# 3061MNNIKA register map
File version: 1.0
Registers are 32-bit, access per field, reset 0x0 unless marked. A register's access mark holds for its fields unless they carry their own. Offsets are from the block's base; [hi:lo] are bit positions.

## I2C0 — I2C peripheral interface
Base 0x14100000
Same registers: I2C1 0x14101000
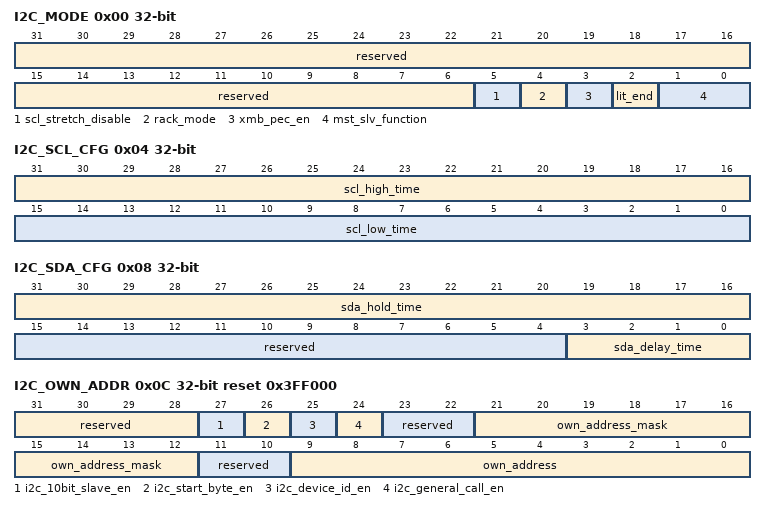
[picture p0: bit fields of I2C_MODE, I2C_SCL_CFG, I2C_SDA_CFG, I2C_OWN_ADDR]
0x00 I2C_MODE — I2C模式配置寄存器。
  [31:6] reserved ro — 保留。
  [5] scl_stretch_disable rw — SCL Stretching使能位。 使能后若如下条件满足，拉低SCL并保持到条件不满足。 不使能时，即使条件满足，SCL也不会被拉低。 该使能位同时对Master和Slave生效。 0：使能； 1：不使能。
  [4] rack_mode rw — 接收ACK/NACK的模式。 0：严格ACK/NACK。如果Master-Transmitter接收到的ACK/NACK与配置的时序命令所期望的ACK/NACK不匹配，那么发出STOP condition，自动退出Master。如果Slave-Transmitter接收到的ACK/NACK与配置的时序命令所期望的ACK/NACK不匹配，那么Slave退出当前I2C帧的通信，SDA输出高阻。 1：忽略ACK/NACK。如果Master-Transmitter，或Slave-Transmitter接收到的ACK/NACK与配置的时序命令所期望的ACK/NACK不匹配，忽略此不匹配，继续下一个时序命令。
  [3] xmb_pec_en rw — SMBus和PMBus的PEC（CRC-8，多项式0x07）计算使能。使能此位后，I2C控制器会自动计算PEC。软件需要通过时序命令控制是否发送PEC和接收PEC。 0：SMBus PEC不使能计算； 1：SMBus PEC使能计算。
  [2] lit_end rw — 数据传输顺序。对Master和Slave功能有效。 0 ：MSbit-First模式； 1 ：LSbit-First模式。
  [1:0] mst_slv_function rw — Master功能和Slave功能选择。 00：控制器不使能； 01：控制器处于Master-only模式； 10：控制器处于Slave-only模式； 11：控制器处于Master-Slave模式。
0x04 I2C_SCL_CFG rw — I2C SCL高低电平时间寄存器。
  [31:16] scl_high_time — SCL高电平时长。Master有效。 建议在标准模式下为SCL周期的1/2，快速模式下为SCL周期的0.36。 标准模式下 (fSCL为SCL时钟线的频率)： scl_high_time = (fclk_i2c/fSCL) x 0.5 - 8 - spike_filter_time 快速模式下 (FSCL为SCL时钟线的频率)： scl_high_time = (fclk_i2c/fSCL) x 0.36 - 8 - spike_filter_time 以参考时钟为100MHz且工作在快速模式下(fSCL = 400kHz)为例，若不滤波，scl_high_time =(100MHz / 400kHz) x 0.36 - 8 = 82。
  [15:0] scl_low_time — SCL低电平时长。Master有效。 建议在标准模式下为SCL周期的1/2，快速模式下为SCL周期的0.64。 标准模式下 (fSCL为SCL时钟线的频率)： scl_low_time = (fclk_i2c/fSCL) x 0.5 - 9 - spike_filter_time 快速模式下 (fSCL为SCL时钟线的频率)： scl_low_time = (fclk_i2c/fSCL) x 0.64 - 9 - spike_filter_time 以参考时钟为100Mhz且工作在快速模式下(fSCL = 400 kHz)为例，若不滤波，，scl_low_time =(100MHz / 400kHz) x 0.64 - 9 = 151。
0x08 I2C_SDA_CFG — I2C SDA时序配置寄存器。
  [31:16] sda_hold_time rw — SDA保持时间配置。 建议配置为sda_hold_duration = i2c_low_duration * 0.3。 注意：只能控制SDA输出的hold time时长。
  [15:4] reserved ro — 保留。
  [3:0] sda_delay_time rw — SDA延迟采样配置。延迟sda_delay_time个clk_i2c工作时钟周期。 注意：对SDA进行delay是指从SDA管脚进来的信号经过寄存后再送给内部控制器。此域决定SDA延迟多少个工作时钟周期后才进行采样。
0x0C I2C_OWN_ADDR reset 0x3FF000 — I2C Slave地址配置寄存器。
  [31:28] reserved ro — 保留。
  [27] i2c_10bit_slave_en rw — I2C控制器Slave接收10bit Slave Addressing (0b1111 0xx)，也正常接收7bit地址。 0：不使能，即7bit寻址模式；Slave将10bit Slave Addressing (0b1111 0xx)视为普通地址，I2C_OWN_ADDR寄存器的own_address位域低7bit和own_address_mask位域低7bit被用于地址检查； 1：使能，即7bit和10bit混合寻址模式。Slave接收10bit Slave Addressing (0b1111 0xx)，视为10bit寻址的第1个地址byte，响应 (返回ACK) 以此地址开始的帧。
  [26] i2c_start_byte_en rw — I2C控制器Slave使能接收START Byte Address。 0：不使能，Slave不接收START Byte Address (0b00000001)，不响应 (返回NACK) 以此地址开始的帧； 1：使能，Slave接收START Byte Address (0b00000001)，根据协议，不响应 (返回NACK) 以此地址开始的帧。
  [25] i2c_device_id_en rw — I2C控制器Slave使能接收Device ID Address。 0：不使能，Slave不接收Device ID Address (0b11111xx1)，不响应(返回NACK)以此地址开始的帧； 1：使能，Slave接收Device ID Address (0b11111xx1)，响应 (返回ACK) 以此地址开始的帧。
  [24] i2c_general_call_en rw — I2C控制器Slave使能接收General Call Address。 0：不使能，Slave不接收General Call Address (0b00000000)，不响应(返回NACK)以此地址开始的帧； 1：使能，Slave接收General Call Address (0b00000000)，响应 (返回ACK) 以此地址开始的帧。
  [23:22] reserved ro — 保留。
  [21:12] own_address_mask rw — I2C控制器Slave的地址掩码。当掩码比特为1，控制器Slave地址相应的比特位参与地址匹配对比。当掩码比特位0，控制器Slave地址相应的比特位不参与地址匹配对比。即，地址匹配的条件：控制器Slave的地址按位与掩码==接收到的地址按位与掩码。
  [11:10] reserved ro — 保留。
  [9:0] own_address rw — I2C控制器Slave的地址。7bit寻址时，低7bit被用于检查地址匹配。10bit寻址时，整个10bit全部被用于检查地址匹配。地址匹配时，响应（返回ACK）Master发出的地址；地址不匹配时，不响应（返回NACK）Master发出的地址。
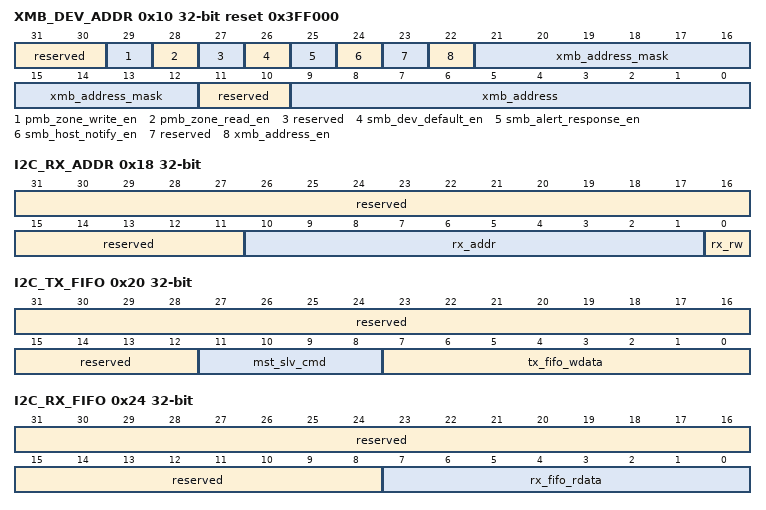
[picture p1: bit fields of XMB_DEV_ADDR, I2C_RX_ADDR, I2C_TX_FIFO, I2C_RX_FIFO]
0x10 XMB_DEV_ADDR reset 0x3FF000 — I2C SMBus PMBus Device专用地址配置寄存器。
  [31:30] reserved ro — 保留。
  [29] pmb_zone_write_en rw — I2C控制器Slave使能接收PMBus ZONE WRITE Address。 0：不使能，Slave不接收PMBus ZONE WRITE Address (0b0110111)，不响应 (返回NACK) 以此地址开始的帧； 1：使能，Slave接收PMBus ZONE WRITE Address (0b0110111)，响应 (返回ACK) 以此地址开始的帧。
  [28] pmb_zone_read_en rw — I2C控制器Slave使能接收PMBus ZONE READ Address。 0：不使能，Slave不接收PMBus ZONE READ Address (0b0101000)，不响应 (返回NACK) 以此地址开始的帧； 1：使能，Slave接收PMBus ZONE READ Address (0b0101000)，响应 (返回ACK) 以此地址开始的帧。
  [27] reserved ro — 保留。
  [26] smb_dev_default_en rw — I2C控制器Slave使能接收SMBus Device Default Address。 0：不使能，Slave不接收SMBus Device Default Address (0b1100001)，不响应 (返回NACK) 以此地址开始的帧； 1：使能，Slave接收SMBus Device Default Address (0b1100001)，响应 (返回ACK)以此地址开始的帧。
  [25] smb_alert_response_en rw — I2C控制器Slave使能接收SMBus Alert Response Address。 0：不使能，Slave不接收SMBus Alert Response Address (0b0001100)，不响应 (返回NACK) 以此地址开始的帧； 1：使能，Slave接收SMBus Alert Response Address (0b0001100)，响应 (返回ACK) 以此地址开始的帧。
  [24] smb_host_notify_en rw — I2C控制器Slave使能接收SMBus Host Address。 0：不使能，Slave不接收SMBus Host Address (0b0001000)，不响应 (返回NACK) 以此地址开始的帧； 1：使能，Slave接收SMBus Host Address (0b0001000)，响应 (返回ACK) 以此地址开始的帧。
  [23] reserved ro — 保留。
  [22] xmb_address_en rw — I2C SMBus PMBus Device专用地址使能。 0：不使能，Slave不接收xmb_address，不响应 (返回NACK)。 1：使能，Slave接收xmb_address，掩码后匹配时，响应 (返回ACK)。
  [21:12] xmb_address_mask rw — I2C SMBus PMBus Device专用地址掩码。当掩码比特为1，控制器Slave专用地址相应的比特位参与地址匹配对比。当掩码比特位0，控制器Slave专用地址相应的比特位不参与地址匹配对比。即，地址匹配的条件：控制器Slave的地址按位与掩码==接收到的地址按位与掩码。
  [11:10] reserved ro — 保留。
  [9:0] xmb_address rw — I2C SMBus PMBus Device专用地址。7bit寻址时，低7bit被用于检查地址匹配。10bit寻址时，整个10bit全部被用于检查地址匹配。地址匹配时，响应（返回ACK）Master发出的地址；地址不匹配时，不响应（返回NACK）Master发出的地址。
0x18 I2C_RX_ADDR ro — I2C Slave已接收的地址，R/W比特。
  [31:11] reserved — 保留。
  [10:1] rx_addr — Slave已接收到的地址。
  [0] rx_rw — Slave已接收到的R/W比特。
0x20 I2C_TX_FIFO — I2C TX FIFO。是命令FIFO和TX数据FIFO的入口，FIFO深度16。
  [31:12] reserved ro — 保留。
  [11:8] mst_slv_cmd wo — 该位域是I2C控制器Master时序命令FIFO入口。软件配置mst_start后，Master开始工作，执行Master CMD FIFO中的命令，直到P时序命令执行完成，退出Master功能。同时该位域也是，I2C控制器Slave时序命令FIFO入口。当接收到START condition或者repeated START condition，Master器件发出的地址匹配且R/W位为1，开始执行FIFO中的命令。当Slave检测到Master器件发出STOP condition时，自动结束时序命令的执行。 0x0: MST_INT1 (Master上报时序命令中断1，根据scl_stretch_disable位域的配置，启动Clock Stretch功能，等待软件清除该中断后，才执行下一个时序命令); SLV_INT1 (Slave上报时序命令中断1，根据scl_stretch_disable位域的配置，启动Clock Stretch功能，等待软件清除该中断后，才执行下一个时序命令); 0x1: MST_S (Master发送START condition)； SLV_S (Slave不发送也不接收数据，进入空闲状态，等待下一个(re)START condition和地址)； 0x2: MST_TD_RACK (Master发送1个字节数据, 每个字节发送后接收低电平ACK)； SLV_RD_TACK (Slave接收1个字节数据，每个字节接收后发送低电平ACK)； 0x3: MST_TD_RNACK (Master发送1个字节数据, 字节发送后接收高电平NACK)； SLV_RD_TNACK (Slave接收1个字节数据，字节接收后发送高电平NACK)； 0x4: MST_TD (Master发送1个字节数据, 无应答位)； SLV_RD (Slave接收1个字节数据，无应答位)； 0x5: MST_RD_TACK (Master接收1个字节数据，每个字节接收后发送低电平ACK)； SLV_TD_RACK (Slave发送1个字节数据, 每个字节发送后接收低电平ACK)； 0x6: MST_RD_TNACK (Master接收1个字节数据，字节接收后发送高电平NACK)； SLV_TD_RNACK (Slave发送1个字节数据, 字节发送后接收高电平NACK)； 0x7: MST_RD (Master接收1个字节数据，无应答位)； SLV_TD (Slave发送1个字节数据, 无应答位)； 0x8: 保留； 0x9: 保留； 0xA：MST_TPEC_RACK (Master发送PEC字节，接收低电平ACK)； SLV_RPEC_TACK (Slave接收PEC字节，发送低电平ACK)； 0xB：MST_TPEC_RNACK (Master发送PEC字节，接收高电平NACK)； SLV_RPEC_TNACK (Slave接收PEC字节，发送高电平NACK)； 0xC: 保留； 0xD：MST_RPEC_TACK (Master接收PEC字节，发送低电平ACK)； SLV_TPEC_RACK (Slave发送PEC字节，接收低电平ACK)； 0xE：MST_RPEC_TNACK (Master接收PEC字节，发送高电平NACK)； SLV_TPEC_RNACK (Slave发送PEC字节，接收高电平NACK)； 0xF: MST_P (Master发送STOP condition)； SLV_P (Slave不发送也不接收，进入空闲状态，等待下一个(re)START condition和地址)； 其他：保留。 提醒： 1、 执行发送数据命令后，若TX FIFO为空，控制器自动开启Clock Stretch功能（SCL拉低并保持），直到TX FIFO非空； 2、 执行接收数据命令后，若RX FIFO满了，控制器自动开启Clock Stretch功能（SCL拉低并保持），直到RX FIFO非满。
  [7:0] tx_fifo_wdata wo — TX FIFO入口。只写。 软件写入待发送出去的数据。
0x24 I2C_RX_FIFO ro — I2C RX FIFO。是RX数据FIFO的出口，FIFO深度16。
  [31:8] reserved — 保留。
  [7:0] rx_fifo_rdata — RX FIFO出口。只读。 软件读出I2C总线上收到的数据。
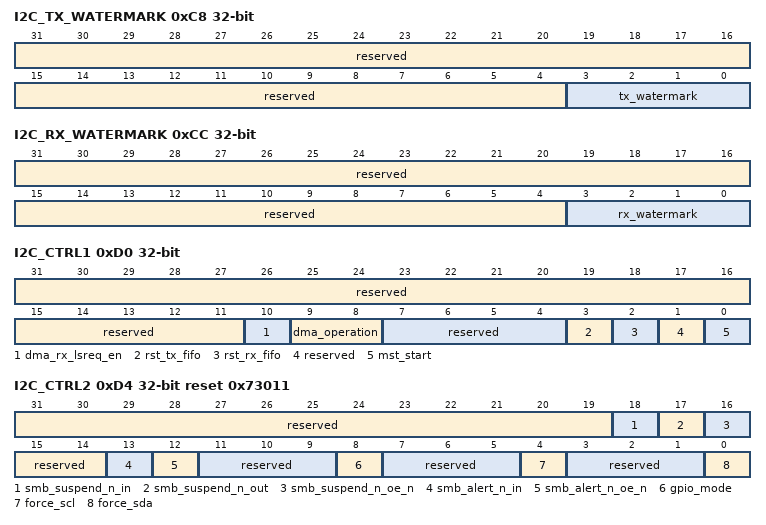
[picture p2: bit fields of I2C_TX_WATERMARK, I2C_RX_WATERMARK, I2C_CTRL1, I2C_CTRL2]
0xC8 I2C_TX_WATERMARK — I2C发送水线寄存器。
  [31:4] reserved ro — 保留。
  [3:0] tx_watermark rw — TX FIFO水线。影响TX FIFO水线中断，和I2C TX FIFO的DMA Burst请求。TX FIFO有效数目小于等于TX FIFO水线时，产生TX FIFO水线原始中断，产生TX FIFO的DMA Burst请求。 0x0：等于0； 0x1：小于或等于1； 0x2：小于或等于2； 0x3：小于或等于3； … 0xF：小于或等于15。
0xCC I2C_RX_WATERMARK — I2C接收水线寄存器。
  [31:4] reserved ro — 保留。
  [3:0] rx_watermark rw — RX FIFO水线。影响RX FIFO水线中断，和I2C RX FIFO的DMA Burst请求。RX FIFO有效数目大于等于RX FIFO水线时，产生RX FIFO水线原始中断，产生RX FIFO的DMA Burst请求。 0x0：大于或等于0； 0x1：大于或等于1； 0x2：大于或等于2； 0x3：大于或等于3； … 0xF：大于或等于15。 注意：该位域配置0时，当RX FIFO为空时也会产生RX FIFO的DMA Burst请求，故DMA传输方式，禁止软件配置为0，否则DMA可能从RX FIFO中读到错误数据。
0xD0 I2C_CTRL1 — I2C控制寄存器1。
  [31:11] reserved ro — 保留。
  [10] dma_rx_lsreq_en rw — DMA I2C模块RX外设流控使能，是否使能I2C模块外设流控请求线。该位域受dma_operation位域控制。 I2C RX外设流控下，当I2C检测到I2C Bus Free（总线空闲）后，通过I2C RX外设流控请求线， 通知DMA搬移最后1个数据，DMA搬移完成后自动关闭通道。 0：不使能I2C RX外设流控，外设流控请求线无效； 1：使能I2C RX外设流控，I2C模块通过外设流控请求线通知DMA发起最后1次RX的Single传输。
  [9:8] dma_operation rw — DMA操作控制。TX FIFO的DMA Single请求产生条件：TX FIFO非满。TX FIFO的DMA Burst请求产生条件：TX FIFO有效数目小于等于配置的TX FIFO水线。RX FIFO的DMA Single请求产生条件：RX FIFO非空。RX FIFO的DMA Burst请求产生条件：RX FIFO有效数目大于等于配置的RX FIFO水线 00：非DMA方式； 01：禁能TX FIFO的DMA Single请求和Burst请求，使能RX FIFO的DMA Single请求和Burst请求； 10：使能TX FIFO的DMA Single请求和Burst请求，禁能RX FIFO的DMA Single请求和Burst请求； 11：同时使能RX FIFO和TX FIFO的DMA Single请求和Burst请求。
  [7:4] reserved ro — 保留。
  [3] rst_tx_fifo rw write-1-clears — 复位TX FIFO。写1生效，清空TX FIFO。 0: 清空完成； 1：清空进行中。
  [2] rst_rx_fifo rw write-1-clears — 复位RX FIFO。写1生效，清空RX FIFO。 0: 清空完成； 1：清空进行中。
  [1] reserved ro — 保留。
  [0] mst_start rw — Master启动控制。此位仅在控制器处于Master-only和Master-slave模式下生效。写1开始Master功能，等待TX FIFO非空时执行Master命令，当P命令执行完毕或者异常后会自动把此位清0。 0：不启动Master，当P命令执行完毕，或者总裁丢失，或者ACK不匹配，自动清0； 1：启动Master，等待TX FIFO非空时执行Master命令。
0xD4 I2C_CTRL2 reset 0x73011 — I2C控制寄存器2。
  [31:19] reserved ro — 保留。
  [18] smb_suspend_n_in ro — SMBus SMBSUS#输入值。 0：低电平输入； 1：高电平输入。
  [17] smb_suspend_n_out rw — SMBus SMBSUS#输出值。 0：低电平输出； 1：高电平输出。
  [16] smb_suspend_n_oe_n rw — SMBus SMBSUS#是否输出。 0：Push-Pull输出。 1：不输出，高阻；
  [15:14] reserved ro — 保留。
  [13] smb_alert_n_in ro — SMBus SMBALERT#输入值。 0：低电平输入； 1：高电平输入。
  [12] smb_alert_n_oe_n rw — SMBus SMBALERT#输出值。 0：低电平Open-Drain输出； 1：Open-Drain输出高阻。
  [11:9] reserved ro
  [8] gpio_mode rw — I2C管脚当GPIO使用。 0：I2C管脚不受force_scl和force_sda控制； 1：I2C管脚由force_scl和force_sda控制。
  [7:5] reserved ro — 保留。
  [4] force_scl rw — 强制设置I2C管脚的值。 0：设成0，总线状态一定为0； 1：设成1，总线状态由线上的其他设备决定。
  [3:1] reserved ro — 保留。
  [0] force_sda rw — 强制设置I2C管脚的值。 0：设成0，总线状态一定为0； 1：设成1，总线状态由线上的其他设备决定。
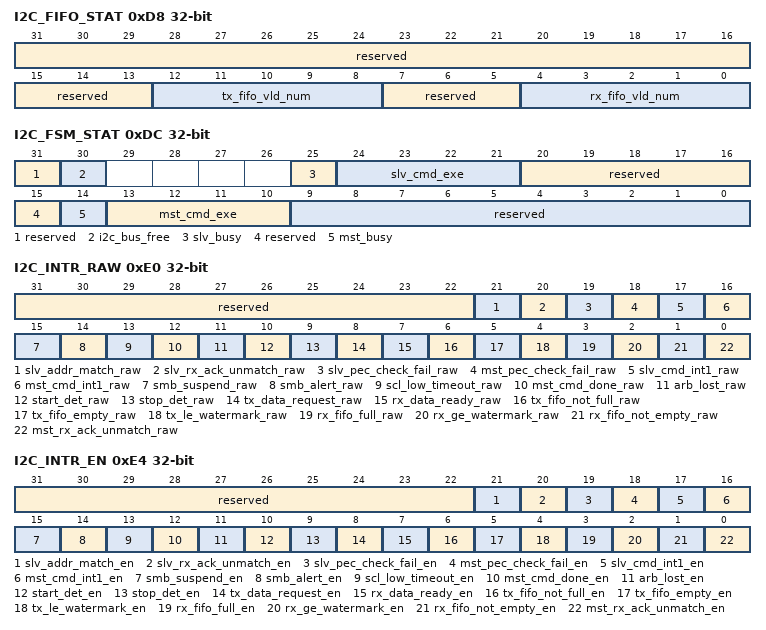
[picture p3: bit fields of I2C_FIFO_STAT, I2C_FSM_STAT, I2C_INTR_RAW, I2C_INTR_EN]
0xD8 I2C_FIFO_STAT ro — I2C FIFO状态寄存器。
  [31:13] reserved — 保留。
  [12:8] tx_fifo_vld_num — TX FIFO里的有效数目。
  [7:5] reserved — 保留。
  [4:0] rx_fifo_vld_num — RX FIFO里的有效数目。
0xDC I2C_FSM_STAT ro — I2C状态机状态寄存器。
  [31] reserved — 保留。
  [30] i2c_bus_free — SCL和SDA处于高电平并持续到达阈值时间，控制器认为总线空闲。软件可配置I2C_BUS_FREE调整阈值时间。 0：总线忙； 1：总线空闲。
  [25] slv_busy — Slave忙。Slave检测到总线上有START条件且地址匹配后，Slave进入忙状态。Slave检测到总线上有STOP条件，或者Slave执行S命令，或者Slave执行P命令，Slave退出忙状态。 0：Slave空闲； 1：Slave忙。
  [24:21] slv_cmd_exe — Slave正在执行的时序命令。时序命令的具体含义，请见mst_slv_cmd位域。
  [20:15] reserved — 保留。
  [14] mst_busy — Master忙。Master执行S命令后，Master进入忙状态。Master仲裁丢失或者Master执行完成P命令后，Master退出忙状态。 0：Master空闲； 1：Master忙。
  [13:10] mst_cmd_exe — Master正在执行的时序命令。时序命令的具体含义，请见mst_slv_cmd位域。
  [9:0] reserved — 保留。
0xE0 I2C_INTR_RAW — I2C原始中断寄存器。
  [31:22] reserved ro — 保留。
  [21] slv_addr_match_raw rw write-clears — 当Slave检测到接收到的地址匹配时，产生该原始中断。原始中断&中断使能=中断状态，软件须对原始中断写1清除该中断。 0：未接受到地址，或者地址不匹配； 1：地址匹配。
  [20] slv_rx_ack_unmatch_raw rw write-clears — Slave接收应答位是否符合时序命令预期。写1清除该原始中断。 0：符合预期； 1：不符合预期。
  [19] slv_pec_check_fail_raw rw write-clears — Slave检查接收到PEC错误。 0：PEC正确； 1：PEC错误。
  [18] mst_pec_check_fail_raw rw write-clears — Master检查接收到PEC错误。 0：PEC正确； 1：PEC错误。
  [17] slv_cmd_int1_raw rw write-clears — Slave时序命令中断1，Slave执行INT1命令时产生此原始中断。写1清除该原始中断。 0：无中断； 1：有中断。
  [16] mst_cmd_int1_raw rw write-clears — Master时序命令中断1，Master执行INT1命令时产生此原始中断。写1清除该原始中断。 0：无中断； 1：有中断。
  [15] smb_suspend_raw rw write-clears — 检测到SMBus SMBSUS# 输入信号下降沿。写1清除该原始中断。 0：无中断； 1：有中断。
  [14] smb_alert_raw rw write-clears — 检测到SMBus SMBALERT# 输入信号下降沿。写1清除该原始中断。 0：无中断； 1：有中断。
  [13] scl_low_timeout_raw rw write-clears — 检测到SCL低电平超时。写1清除该原始中断。 0 ：无中断； 1 ：有中断。
  [12] mst_cmd_done_raw rw write-clears — Master时序命令正常完成，Master执行完成P时序命令时产生此原始中断。写1清除该原始中断。 0 ：无中断； 1 ：有中断。
  [11] arb_lost_raw rw write-clears — 仲裁丢失。写1清除该原始中断。 0 ：无中断； 1 ：有中断。
  [10] start_det_raw rw write-clears — 检查到START。写1清除该原始中断。 0 ：无中断； 1 ：有中断。
  [9] stop_det_raw rw write-clears — 检查到STOP。写1清除该原始中断。 0 ：无中断； 1 ：有中断。
  [8] tx_data_request_raw rw write-clears — TX FIFO请求新的命令和数据。此时发生Clock Stretching，暂停总线。写1清除该原始中断。 0 ：无中断； 1 ：有中断。
  [7] rx_data_ready_raw rw write-clears — RX FIFO接收到了新的数据。写1清除该原始中断。 0 ：无中断； 1 ：有中断。
  [6] tx_fifo_not_full_raw rw write-clears — TX FIFO非满。写1清除该原始中断。 0 ：无中断； 1 ：有中断。
  [5] tx_fifo_empty_raw rw write-clears — TX FIFO空。写1清除该原始中断。 0 ：无中断； 1 ：有中断。
  [4] tx_le_watermark_raw rw write-clears — TX FIFO里的数据个数小于等于水线。写1清除该原始中断。 0 ：无中断； 1 ：有中断。
  [3] rx_fifo_full_raw rw write-clears — RX FIFO满。写1清除该原始中断。 0 ：无中断； 1 ：有中断。
  [2] rx_ge_watermark_raw rw write-clears — RX FIFO里的数据个数大于等于水线。写1清除该原始中断。 0 ：无中断； 1 ：有中断。
  [1] rx_fifo_not_empty_raw rw write-clears — RX FIFO非空。写1清除该原始中断。 0 ：无中断； 1 ：有中断。
  [0] mst_rx_ack_unmatch_raw rw write-clears — Master接收应答位是否符合时序命令预期。写1清除该原始中断。 0：符合预期； 1：不符合预期。
0xE4 I2C_INTR_EN — I2C中断使能寄存器。
  [31:22] reserved ro — 保留。
  [21] slv_addr_match_en rw — slv_addr_match中断使能。中断状态=原始中断&中断使能。 0：不使能； 1：使能。
  [20] slv_rx_ack_unmatch_en rw — slv_rx_ack_unmatch中断使能。中断状态=原始中断&中断使能。 0：不使能； 1：使能。
  [19] slv_pec_check_fail_en rw — slv_pec_check_fail中断使能。中断状态=原始中断&中断使能。 0：不使能； 1：使能。
  [18] mst_pec_check_fail_en rw — mst_pec_check_fail中断使能。中断状态=原始中断&中断使能。 0：不使能； 1：使能。
  [17] slv_cmd_int1_en rw — Slave时序命令中断1使能。中断状态=原始中断&中断使能。 0：不使能； 1：使能。
  [16] mst_cmd_int1_en rw — Master时序命令中断1使能。中断状态=原始中断&中断使能。 0：不使能； 1：使能。
  [15] smb_suspend_en rw — smb_suspend中断使能。中断状态=原始中断&中断使能。 0：不使能； 1：使能。
  [14] smb_alert_en rw — smb_alert中断使能。中断状态=原始中断&中断使能。 0：不使能； 1：使能。
  [13] scl_low_timeout_en rw — SCL低电平超时中断使能。中断状态=原始中断&中断使能。 0：不使能； 1：使能。
  [12] mst_cmd_done_en rw — mst_cmd_done中断使能。中断状态=原始中断&中断使能。 0 ：不使能； 1 ：使能。
  [11] arb_lost_en rw — arb_lost中断使能。中断状态=原始中断&中断使能。 0 ：不使能； 1 ：使能。
  [10] start_det_en rw — start_det中断使能。中断状态=原始中断&中断使能。 0 ：不使能； 1 ：使能。
  [9] stop_det_en rw — stop中断使能。中断状态=原始中断&中断使能。 0 ：不使能； 1 ：使能。
  [8] tx_data_request_en rw — tx_data_request中断使能。中断状态=原始中断&中断使能。 0 ：不使能； 1 ：使能。
  [7] rx_data_ready_en rw — rx_data_ready中断使能。中断状态=原始中断&中断使能。 0 ：不使能； 1 ：使能。
  [6] tx_fifo_not_full_en rw — tx_fifo_not_full中断使能。中断状态=原始中断&中断使能。 0 ：不使能； 1 ：使能。
  [5] tx_fifo_empty_en rw — tx_fifo_empty中断使能。中断状态=原始中断&中断使能。 0 ：不使能； 1 ：使能。
  [4] tx_le_watermark_en rw — tx_le_watermark中断使能。中断状态=原始中断&中断使能。 0 ：不使能； 1 ：使能。
  [3] rx_fifo_full_en rw — rx_fifo_full中断使能。中断状态=原始中断&中断使能。 0 ：不使能； 1 ：使能。
  [2] rx_ge_watermark_en rw — rx_ge_watermark中断使能。中断状态=原始中断&中断使能。 0 ：不使能； 1 ：使能。
  [1] rx_fifo_not_empty_en rw — rx_fifo_not_empty中断使能。中断状态=原始中断&中断使能。 0 ：不使能； 1 ：使能。
  [0] mst_rx_ack_unmatch_en rw — mst_ack_unmatch中断使能。中断状态=原始中断&中断使能。 0 ：不使能； 1 ：使能。
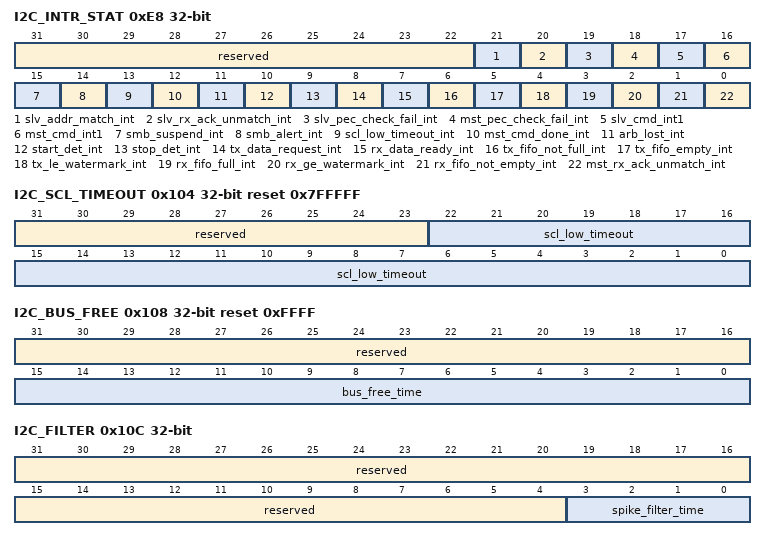
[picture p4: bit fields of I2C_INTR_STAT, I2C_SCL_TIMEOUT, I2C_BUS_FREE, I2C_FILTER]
0xE8 I2C_INTR_STAT ro — I2C中断状态寄存器。
  [31:22] reserved — 保留。
  [21] slv_addr_match_int — Slave检测到接收到的地址匹配。 0：无中断； 1：有中断。
  [20] slv_rx_ack_unmatch_int — Slave接收应答位是否符合时序命令预期。 0：无中断； 1：有中断。
  [19] slv_pec_check_fail_int — Slave检查接收到PEC错误。 0：无中断； 1：有中断。
  [18] mst_pec_check_fail_int — Master检查接收到PEC错误。 0：无中断； 1：有中断。
  [17] slv_cmd_int1 — Slave时序命令中断1。 0：无中断； 1：有中断。
  [16] mst_cmd_int1 — Master时序命令中断1。 0：无中断； 1：有中断。
  [15] smb_suspend_int — 检测到SMBus SMBSUS# 输入信号下降沿。 0：无中断； 1：有中断。
  [14] smb_alert_int — 检测到SMBus SMBALERT# 输入信号下降沿。 0：无中断； 1：有中断。
  [13] scl_low_timeout_int — SCL低电平超时中断。 0：无中断； 1：有中断。
  [12] mst_cmd_done_int — Master时序命令正常完成。 0 ：无中断； 1 ：有中断。
  [11] arb_lost_int — 仲裁丢失。 0 ：无中断； 1 ：有中断。
  [10] start_det_int — 检查到START。 0 ：无中断； 1 ：有中断。
  [9] stop_det_int — 检查到STOP。 0 ：无中断； 1 ：有中断。
  [8] tx_data_request_int — TX FIFO请求新的数据。当Master-Transmitter或者Slave-Transmitter发送数据，但是TX FIFO空，此时发生Clock Stretching，暂停总线，并产生该中断。 0 ：无中断； 1 ：有中断。
  [7] rx_data_ready_int — RX FIFO接收了新的数据。当Master-Receiver或者Slave-Receiver接收到了新的数据，产生该中断。 0 ：无中断； 1 ：有中断。
  [6] tx_fifo_not_full_int — TX FIFO非满。 0 ：无中断； 1 ：有中断。
  [5] tx_fifo_empty_int — TX FIFO空。 0 ：无中断； 1 ：有中断。
  [4] tx_le_watermark_int — TX FIFO里的数据个数小于等于水线。 0 ：无中断； 1 ：有中断。
  [3] rx_fifo_full_int — RX FIFO满。 0 ：无中断； 1 ：有中断。
  [2] rx_ge_watermark_int — RX FIFO里的数据个数大于等于水线。 0 ：无中断； 1 ：有中断。
  [1] rx_fifo_not_empty_int — RX FIFO非空。 0 ：无中断； 1 ：有中断。
  [0] mst_rx_ack_unmatch_int — 应答位是否符合预期。 0：符合预期； 1：不符合预期。
0x100 I2C_VERSION ro reset 0x1 — I2C版本号寄存器。
  [31:0] version — I2C控制器版本号。
0x104 I2C_SCL_TIMEOUT reset 0x7FFFFF — I2C SCL超时阈值寄存器。
  [31:23] reserved ro — 保留。
  [22:0] scl_low_timeout rw — SCL低电平超时配置。单位为I2C工作时钟周期。超时后，产生SCL低电平超时原始中断scl_low_timeout_raw。 0x0：0个I2C工作时钟周期； 0x1：1个I2C工作时钟周期； … 0x7FFFFF：8388607个I2C工作时钟周期。
0x108 I2C_BUS_FREE reset 0xFFFF — I2C总线空闲阈值寄存器。
  [31:16] reserved ro — 保留。
  [15:0] bus_free_time rw — 总线空闲阈值。单位为I2C工作时钟周期。控制器检测到STOP条件后，SCL和SDA同时为高电平并持续到达阈值时间，控制器认为总线空闲。 注意：控制器Master功能只有在总线空闲时才能发送命令代号为MST_S的时序命令。 0x0：0个I2C工作时钟周期； 0x1：1个I2C工作时钟周期； … 0xFFFF：65535个I2C工作时钟周期。
0x10C I2C_FILTER — I2C SDA和SCL滤波配置寄存器。
  [31:4] reserved ro — 保留。
  [3:0] spike_filter_time rw — SDA和SCL毛刺过滤配置。 0x0：不过滤毛刺； 0x1：过滤1个I2C工作时钟周期的毛刺； 0x2：过滤2个I2C工作时钟周期的毛刺； … 0xF：过滤15个I2C工作时钟周期的毛刺。
